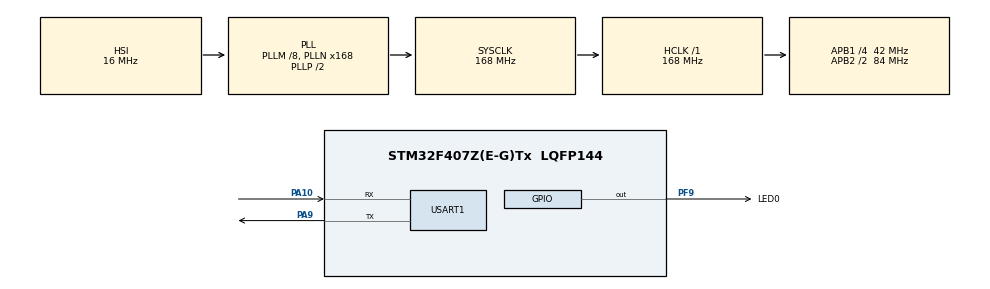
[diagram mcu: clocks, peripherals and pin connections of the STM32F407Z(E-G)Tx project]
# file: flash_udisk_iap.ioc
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Mcu.Family=STM32F4
Mcu.Name=STM32F407Z(E-G)Tx
Mcu.Package=LQFP144
NVIC.PriorityGroup=NVIC_PRIORITYGROUP_4
PA10.Mode=Asynchronous
PA10.Signal=USART1_RX
PA13.Mode=Serial_Wire
PA13.Signal=SYS_JTMS-SWDIO
PA14.Mode=Serial_Wire
PA14.Signal=SYS_JTCK-SWCLK
PA9.Mode=Asynchronous
PA9.Signal=USART1_TX
PF9.GPIO_Label=LED0
PF9.Signal=GPIO_Output
PH0-OSC_IN.Mode=HSE-External-Oscillator
PH0-OSC_IN.Signal=RCC_OSC_IN
PH1-OSC_OUT.Mode=HSE-External-Oscillator
PH1-OSC_OUT.Signal=RCC_OSC_OUT
ProjectManager.HeapSize=0x200
ProjectManager.StackSize=0x400
ProjectManager.TargetToolchain=STM32CubeIDE
RCC.48MHZClocksFreq_Value=84000000
RCC.AHBFreq_Value=168000000
RCC.APB1CLKDivider=RCC_HCLK_DIV4
RCC.APB1Freq_Value=42000000
RCC.APB1TimFreq_Value=84000000
RCC.APB2CLKDivider=RCC_HCLK_DIV2
RCC.APB2Freq_Value=84000000
RCC.APB2TimFreq_Value=168000000
RCC.CortexFreq_Value=168000000
RCC.HCLKFreq_Value=168000000
RCC.HSE_VALUE=25000000
RCC.HSI_VALUE=16000000
RCC.LSE_VALUE=32768
RCC.PLLM=8
RCC.PLLN=168
RCC.SYSCLKFreq_VALUE=168000000
RCC.SYSCLKSource=RCC_SYSCLKSOURCE_PLLCLK
RCC.VCOOutputFreq_Value=336000000
USART1.VirtualMode=VM_ASYNC
board=custom

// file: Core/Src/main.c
/* USER CODE BEGIN Header */
/**
  ******************************************************************************
  * @file           : main.c
  * @brief          : Main program body
  ******************************************************************************
  * @attention
  *
  * <h2><center>&copy; Copyright (c) 2020 STMicroelectronics.
  * All rights reserved.</center></h2>
  *
  * This software component is licensed by ST under BSD 3-Clause license,
  * the "License"; You may not use this file except in compliance with the
  * License. You may obtain a copy of the License at:
  *                        opensource.org/licenses/BSD-3-Clause
  *
  ******************************************************************************
  */
/* USER CODE END Header */

#include "main.h"
#include "Delayer.h"
#include "Logger.h"

UART_HandleTypeDef huart1;

/* USER CODE BEGIN PV */
static ST_DELAYER sDelayerLED;
/* USER CODE END PV */

void SystemClock_Config(void);
static void MX_GPIO_Init(void);
static void MX_USART1_UART_Init(void);

int main(void)
{

  /* MCU Configuration--------------------------------------------------------*/

  /* Reset of all peripherals, Initializes the Flash interface and the Systick. */
  HAL_Init();

  /* Configure the system clock */
  SystemClock_Config();

  /* Initialize all configured peripherals */
  MX_GPIO_Init();
  MX_USART1_UART_Init();

  /* Infinite loop */
  /* USER CODE BEGIN WHILE */
  SetDelayer(&sDelayerLED, 200, E_DELAYER_LOOP);
  while (1)
  {
    /* USER CODE END WHILE */
    if(E_DELAYER_TIMEOUT == CheckTimeout(&sDelayerLED)){
    	CPrintfToLog("hello world\r\n");
        HAL_GPIO_TogglePin(LED0_GPIO_Port, LED0_Pin);
    }

    HAL_Delay(100);
  }
}

void SystemClock_Config(void)
{
  RCC_OscInitTypeDef RCC_OscInitStruct = {0};
  RCC_ClkInitTypeDef RCC_ClkInitStruct = {0};

  /** Configure the main internal regulator output voltage
  */
  __HAL_RCC_PWR_CLK_ENABLE();
  __HAL_PWR_VOLTAGESCALING_CONFIG(PWR_REGULATOR_VOLTAGE_SCALE1);
  /** Initializes the CPU, AHB and APB busses clocks
  */
  RCC_OscInitStruct.OscillatorType = RCC_OSCILLATORTYPE_HSI;
  RCC_OscInitStruct.HSIState = RCC_HSI_ON;
  RCC_OscInitStruct.HSICalibrationValue = RCC_HSICALIBRATION_DEFAULT;
  RCC_OscInitStruct.PLL.PLLState = RCC_PLL_ON;
  RCC_OscInitStruct.PLL.PLLSource = RCC_PLLSOURCE_HSI;
  RCC_OscInitStruct.PLL.PLLM = 8;
  RCC_OscInitStruct.PLL.PLLN = 168;
  RCC_OscInitStruct.PLL.PLLP = RCC_PLLP_DIV2;
  RCC_OscInitStruct.PLL.PLLQ = 4;
  if (HAL_RCC_OscConfig(&RCC_OscInitStruct) != HAL_OK)
  {
    Error_Handler();
  }
  /** Initializes the CPU, AHB and APB busses clocks
  */
  RCC_ClkInitStruct.ClockType = RCC_CLOCKTYPE_HCLK|RCC_CLOCKTYPE_SYSCLK
                              |RCC_CLOCKTYPE_PCLK1|RCC_CLOCKTYPE_PCLK2;
  RCC_ClkInitStruct.SYSCLKSource = RCC_SYSCLKSOURCE_PLLCLK;
  RCC_ClkInitStruct.AHBCLKDivider = RCC_SYSCLK_DIV1;
  RCC_ClkInitStruct.APB1CLKDivider = RCC_HCLK_DIV4;
  RCC_ClkInitStruct.APB2CLKDivider = RCC_HCLK_DIV2;

  if (HAL_RCC_ClockConfig(&RCC_ClkInitStruct, FLASH_LATENCY_5) != HAL_OK)
  {
    Error_Handler();
  }
}

static void MX_USART1_UART_Init(void)
{

  huart1.Instance = USART1;
  huart1.Init.BaudRate = 115200;
  huart1.Init.WordLength = UART_WORDLENGTH_8B;
  huart1.Init.StopBits = UART_STOPBITS_1;
  huart1.Init.Parity = UART_PARITY_NONE;
  huart1.Init.Mode = UART_MODE_TX_RX;
  huart1.Init.HwFlowCtl = UART_HWCONTROL_NONE;
  huart1.Init.OverSampling = UART_OVERSAMPLING_16;
  if (HAL_UART_Init(&huart1) != HAL_OK)
  {
    Error_Handler();
  }

}

static void MX_GPIO_Init(void)
{
  GPIO_InitTypeDef GPIO_InitStruct = {0};

  /* GPIO Ports Clock Enable */
  __HAL_RCC_GPIOF_CLK_ENABLE();
  __HAL_RCC_GPIOH_CLK_ENABLE();
  __HAL_RCC_GPIOA_CLK_ENABLE();

  /*Configure GPIO pin Output Level */
  HAL_GPIO_WritePin(LED0_GPIO_Port, LED0_Pin, GPIO_PIN_RESET);

  /*Configure GPIO pin : LED0_Pin */
  GPIO_InitStruct.Pin = LED0_Pin;
  GPIO_InitStruct.Mode = GPIO_MODE_OUTPUT_PP;
  GPIO_InitStruct.Pull = GPIO_NOPULL;
  GPIO_InitStruct.Speed = GPIO_SPEED_FREQ_LOW;
  HAL_GPIO_Init(LED0_GPIO_Port, &GPIO_InitStruct);

}

void Error_Handler(void)
{
}

/************************ (C) COPYRIGHT STMicroelectronics *****END OF FILE****/
